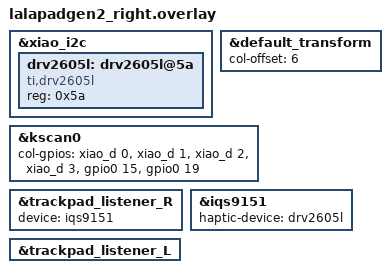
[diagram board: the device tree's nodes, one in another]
#include "lalapadgen2.dtsi"

&xiao_i2c {
    drv2605l: drv2605l@5a {
        compatible = "ti,drv2605l";
        reg = <0x5a>;
        status = "okay";
    };
};

&default_transform {
    col-offset = <6>;
};

&kscan0 {
    col-gpios
        = <&xiao_d 0 GPIO_ACTIVE_HIGH>
        , <&xiao_d 1 GPIO_ACTIVE_HIGH>
        , <&xiao_d 2 GPIO_ACTIVE_HIGH>
        , <&xiao_d 3 GPIO_ACTIVE_HIGH>
        , <&gpio0 15 GPIO_ACTIVE_HIGH>
        , <&gpio0 19 GPIO_ACTIVE_HIGH>
        ;
};

&trackpad_listener_R {
    status = "okay";
    device = <&iqs9151>;
};

&iqs9151 {
    haptic-device = <&drv2605l>;
};

&trackpad_listener_L {
    status = "okay";
};
